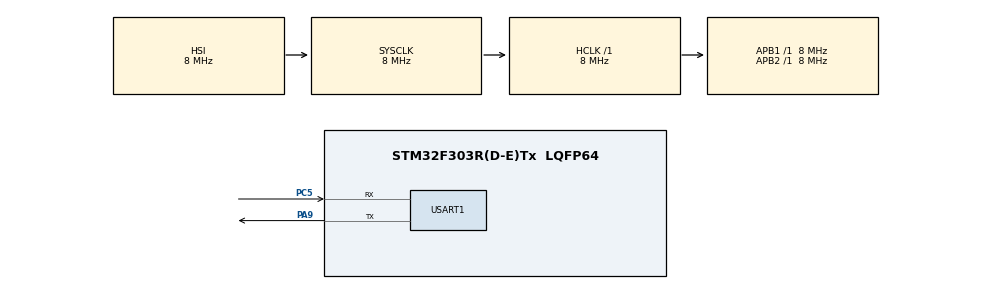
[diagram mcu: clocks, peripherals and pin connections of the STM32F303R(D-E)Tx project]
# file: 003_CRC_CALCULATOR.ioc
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Mcu.Family=STM32F3
Mcu.Name=STM32F303R(D-E)Tx
Mcu.Package=LQFP64
NVIC.PriorityGroup=NVIC_PRIORITYGROUP_4
PA9.Mode=Asynchronous
PA9.Signal=USART1_TX
PC5.Mode=Asynchronous
PC5.Signal=USART1_RX
ProjectManager.HeapSize=0x200
ProjectManager.StackSize=0x400
ProjectManager.TargetToolchain=STM32CubeIDE
RCC.AHBFreq_Value=8000000
RCC.APB1Freq_Value=8000000
RCC.APB2Freq_Value=8000000
RCC.CortexFreq_Value=8000000
RCC.HSE_VALUE=8000000
RCC.HSI_VALUE=8000000
RCC.LSE_VALUE=32768
RCC.SYSCLKFreq_VALUE=8000000
RCC.USBFreq_Value=16000000
USART1.VirtualMode-Asynchronous=VM_ASYNC
VP_CRC_VS_CRC.Mode=CRC_Activate
board=custom

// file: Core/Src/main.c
/* USER CODE BEGIN Header */
/**
  ******************************************************************************
  * @file           : main.c
  * @brief          : Main program body
  ******************************************************************************
  * @attention
  *
  * Copyright (c) 2025 STMicroelectronics.
  * All rights reserved.
  *
  * This software is licensed under terms that can be found in the LICENSE file
  * in the root directory of this software component.
  * If no LICENSE file comes with this software, it is provided AS-IS.
  *
  ******************************************************************************
  */
/* USER CODE END Header */
#include "main.h"

CRC_HandleTypeDef hcrc;

UART_HandleTypeDef huart1;

void SystemClock_Config(void);
static void MX_GPIO_Init(void);
static void MX_CRC_Init(void);
static void MX_USART1_UART_Init(void);

int main(void)
{

  /* MCU Configuration--------------------------------------------------------*/

  /* Reset of all peripherals, Initializes the Flash interface and the Systick. */
  HAL_Init();

  /* Configure the system clock */
  SystemClock_Config();

  /* Initialize all configured peripherals */
  MX_GPIO_Init();
  MX_CRC_Init();
  MX_USART1_UART_Init();
  /* USER CODE BEGIN 2 */

  //uint32_t data32[] = {0xA501FF22};
  //uint32_t data32 = 0xA501FF22;
  //uint8_t tx_buf[] = {0x22, 0xFF, 0x01, 0xA5};
  //uint32_t tx_buf[] = {0x1A2B3C4D};
  //uint8_t data[] = { 0x1A, 0x2B, 0x3C, 0x4D };

  //uint8_t tx_buf[] = {0xA5, 0x01, 0xFF, 0x22};
  //uint8_t tx_buf[] = {0xD4, 0x58, 0xB2, 0x3C};
  uint8_t data[2] = {0x05, 0x51};
  uint32_t data32;

  // Byte dizisini 32-bit hizalamak için padding yapılır:
  data32 =  (uint32_t)data[0] << 16|
           ((uint32_t)data[1] << 24);  // 0x00005105 olur (Little Endian)

  __HAL_CRC_DR_RESET(&hcrc);  // CRC birimini sıfırla
  uint32_t crc = HAL_CRC_Accumulate(&hcrc, &data32, 1);  // 1 x 32-bit word

  // UART ile gönder
  HAL_UART_Transmit(&huart1, (uint8_t *)&crc, 4, HAL_MAX_DELAY);

  /* USER CODE END 2 */

  /* Infinite loop */
  while (1)
  {

  }
}

void SystemClock_Config(void)
{
  RCC_OscInitTypeDef RCC_OscInitStruct = {0};
  RCC_ClkInitTypeDef RCC_ClkInitStruct = {0};
  RCC_PeriphCLKInitTypeDef PeriphClkInit = {0};

  /** Initializes the RCC Oscillators according to the specified parameters
  * in the RCC_OscInitTypeDef structure.
  */
  RCC_OscInitStruct.OscillatorType = RCC_OSCILLATORTYPE_HSI;
  RCC_OscInitStruct.HSIState = RCC_HSI_ON;
  RCC_OscInitStruct.HSICalibrationValue = RCC_HSICALIBRATION_DEFAULT;
  RCC_OscInitStruct.PLL.PLLState = RCC_PLL_NONE;
  if (HAL_RCC_OscConfig(&RCC_OscInitStruct) != HAL_OK)
  {
    Error_Handler();
  }

  /** Initializes the CPU, AHB and APB buses clocks
  */
  RCC_ClkInitStruct.ClockType = RCC_CLOCKTYPE_HCLK|RCC_CLOCKTYPE_SYSCLK
                              |RCC_CLOCKTYPE_PCLK1|RCC_CLOCKTYPE_PCLK2;
  RCC_ClkInitStruct.SYSCLKSource = RCC_SYSCLKSOURCE_HSI;
  RCC_ClkInitStruct.AHBCLKDivider = RCC_SYSCLK_DIV1;
  RCC_ClkInitStruct.APB1CLKDivider = RCC_HCLK_DIV1;
  RCC_ClkInitStruct.APB2CLKDivider = RCC_HCLK_DIV1;

  if (HAL_RCC_ClockConfig(&RCC_ClkInitStruct, FLASH_LATENCY_0) != HAL_OK)
  {
    Error_Handler();
  }
  PeriphClkInit.PeriphClockSelection = RCC_PERIPHCLK_USART1;
  PeriphClkInit.Usart1ClockSelection = RCC_USART1CLKSOURCE_PCLK2;
  if (HAL_RCCEx_PeriphCLKConfig(&PeriphClkInit) != HAL_OK)
  {
    Error_Handler();
  }
}

static void MX_CRC_Init(void)
{

  hcrc.Instance = CRC;
  hcrc.Init.DefaultPolynomialUse = DEFAULT_POLYNOMIAL_ENABLE;
  hcrc.Init.DefaultInitValueUse = DEFAULT_INIT_VALUE_ENABLE;
  hcrc.Init.InputDataInversionMode = CRC_INPUTDATA_INVERSION_NONE;
  hcrc.Init.OutputDataInversionMode = CRC_OUTPUTDATA_INVERSION_DISABLE;
  hcrc.InputDataFormat = CRC_INPUTDATA_FORMAT_BYTES;
  if (HAL_CRC_Init(&hcrc) != HAL_OK)
  {
    Error_Handler();
  }

}

static void MX_USART1_UART_Init(void)
{

  huart1.Instance = USART1;
  huart1.Init.BaudRate = 38400;
  huart1.Init.WordLength = UART_WORDLENGTH_8B;
  huart1.Init.StopBits = UART_STOPBITS_1;
  huart1.Init.Parity = UART_PARITY_NONE;
  huart1.Init.Mode = UART_MODE_TX_RX;
  huart1.Init.HwFlowCtl = UART_HWCONTROL_NONE;
  huart1.Init.OverSampling = UART_OVERSAMPLING_16;
  huart1.Init.OneBitSampling = UART_ONE_BIT_SAMPLE_DISABLE;
  huart1.AdvancedInit.AdvFeatureInit = UART_ADVFEATURE_NO_INIT;
  if (HAL_UART_Init(&huart1) != HAL_OK)
  {
    Error_Handler();
  }

}

static void MX_GPIO_Init(void)
{

  /* GPIO Ports Clock Enable */
  __HAL_RCC_GPIOC_CLK_ENABLE();
  __HAL_RCC_GPIOA_CLK_ENABLE();

}

void Error_Handler(void)
{
  __disable_irq();
  while (1)
  {
  }
}
